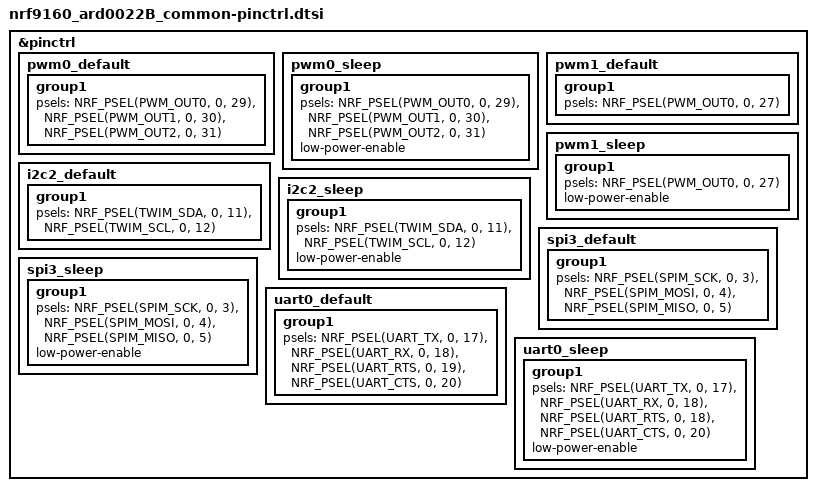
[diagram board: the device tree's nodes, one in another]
//
// Copyright (c) .NET Foundation and Contributors
// Portions Copyright (c) 2019 Nordic Semiconductor ASA
// Portions Copyright (c) Ericsson AB 2020, all rights reserved
// See LICENSE file in the project root for full license information.
//

&pinctrl {
	pwm0_default: pwm0_default {
		group1 {
			psels = <NRF_PSEL(PWM_OUT0, 0, 29)>,
				<NRF_PSEL(PWM_OUT1, 0, 30)>,
				<NRF_PSEL(PWM_OUT2, 0, 31)>;
		};
	};

	pwm0_sleep: pwm0_sleep {
		group1 {
			psels = <NRF_PSEL(PWM_OUT0, 0, 29)>,
				<NRF_PSEL(PWM_OUT1, 0, 30)>,
				<NRF_PSEL(PWM_OUT2, 0, 31)>;
			low-power-enable;
		};
	};

	pwm1_default: pwm1_default {
		group1 {
			psels = <NRF_PSEL(PWM_OUT0, 0, 27)>;
		};
	};

	pwm1_sleep: pwm1_sleep {
		group1 {
			psels = <NRF_PSEL(PWM_OUT0, 0, 27)>;
			low-power-enable;
		};
	};

	i2c2_default: i2c2_default {
		group1 {
			psels = <NRF_PSEL(TWIM_SDA, 0, 11)>,
				<NRF_PSEL(TWIM_SCL, 0, 12)>;
		};
	};

	i2c2_sleep: i2c2_sleep {
		group1 {
			psels = <NRF_PSEL(TWIM_SDA, 0, 11)>,
				<NRF_PSEL(TWIM_SCL, 0, 12)>;
			low-power-enable;
		};
	};

	spi3_default: spi3_default {
		group1 {
			psels = <NRF_PSEL(SPIM_SCK, 0, 3)>,
				<NRF_PSEL(SPIM_MOSI, 0, 4)>,
				<NRF_PSEL(SPIM_MISO, 0, 5)>;
		};
	};

	spi3_sleep: spi3_sleep {
		group1 {
			psels = <NRF_PSEL(SPIM_SCK, 0, 3)>,
				<NRF_PSEL(SPIM_MOSI, 0, 4)>,
				<NRF_PSEL(SPIM_MISO, 0, 5)>;
			low-power-enable;
		};
	};

	uart0_default: uart0_default {
		group1 {
			psels = <NRF_PSEL(UART_TX, 0, 17)>,
				<NRF_PSEL(UART_RX, 0, 18)>,
				<NRF_PSEL(UART_RTS, 0, 19)>,
				<NRF_PSEL(UART_CTS, 0, 20)>;
		};
	};

	uart0_sleep: uart0_sleep {
		group1 {
			psels = <NRF_PSEL(UART_TX, 0, 17)>,
				<NRF_PSEL(UART_RX, 0, 18)>,
				<NRF_PSEL(UART_RTS, 0, 18)>,
				<NRF_PSEL(UART_CTS, 0, 20)>;
			low-power-enable;
		};
	};

};
